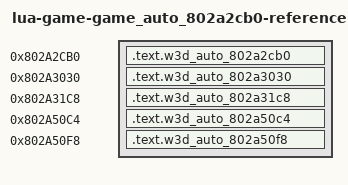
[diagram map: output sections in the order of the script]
/* Generated reference-only placements. All bodies are source-built. */
OUTPUT_FORMAT("elf32-powerpc")
OUTPUT_ARCH(powerpc)
ENTRY(w3d_auto_802a2cb0)
_SDA_BASE_ = 0x804b2540;
_SDA2_BASE_ = 0x804c2540;
fn_8015FD1C = 0x8015fd1c;
fn_802B0668 = 0x802b0668;
fn_802B15E0 = 0x802b15e0;
fn_802B1BD0 = 0x802b1bd0;
fn_802B1F98 = 0x802b1f98;
SECTIONS {
  .text.w3d_auto_802a2cb0 0x802a2cb0 : { *(.text.w3d_auto_802a2cb0) }
  .text.w3d_auto_802a3030 0x802a3030 : { *(.text.w3d_auto_802a3030) }
  .text.w3d_auto_802a31c8 0x802a31c8 : { *(.text.w3d_auto_802a31c8) }
  .text.w3d_auto_802a50c4 0x802a50c4 : { *(.text.w3d_auto_802a50c4) }
  .text.w3d_auto_802a50f8 0x802a50f8 : { *(.text.w3d_auto_802a50f8) }
  /DISCARD/ : { *(.text*) *(.rodata*) *(.data*) *(.bss*) *(.sdata*) *(.sbss*) *(.comment) }
}
